# nrf9230_application register map
Vendor: Nordic Semiconductor; Series: nRF92; File version: 1
CPU: CM33 r0p4, little endian, MPU, FPU, 3 interrupt priority bits, 480 interrupts, 8 SAU regions
Registers are 32-bit, read-write, reset 0x0 unless marked. A register's access mark holds for its fields unless they carry their own. Offsets are from the block's base; [hi:lo] are bit positions; lines under a group give offsets from that group; {n}, {i} and the like mark numbered series.

## CPUCONF_NS — CPU Configuration 0
Base 0x42011000
Same registers: CPUCONF_S 0x52011000
0x00 TASKS_ERASECACHE wo — Erase the caches used by the CPU.
  [0] TASKS_ERASECACHE
    1=Trigger task
0x500 INITSVTOR reset 0xE0000000 — Initial value of the secure VTOR (Vector Table Offset Register) after CPU reset.
  [31:0] INITSVTOR — Initial value of the VTOR.
0x504 INITNSVTOR reset 0xE0000000 — Initial value of the non-secure VTOR (Vector Table Offset Register).
  [31:0] INITNSVTOR — Initial value of the VTOR.
0x508 CPUSTART — Enable for starting the CPU
  [0] EN — Enable to start the CPU.
    0=Stopped (CPU stopped.); 1=Started (CPU started.)
0x50C CPUWAIT — Enable for the CPU wait.
  [0] EN — Enable to the CPU wait.
    0=Disabled (CPU is not waiting.); 1=Enabled (CPU is waiting.)

## MEMCONF_NS — Memory configuration 0
Base 0x42012000
Same registers: MEMCONF_S 0x52012000
{0x500+0x10*i} POWER[{i}] (i=0..1) group — Unspecified
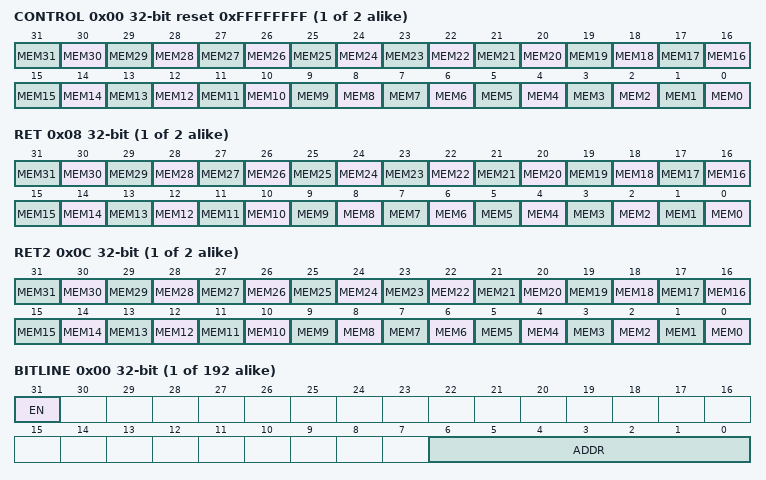
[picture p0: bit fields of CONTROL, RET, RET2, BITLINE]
  0x00 CONTROL reset 0xFFFFFFFF — Description cluster: Control memory block power.
    [all] fields
      0=Off (Power down); 1=On (Power up)
    [n] MEM{n} (n=0..31) — Keep the memory block MEM[{n}] on or off when in System ON mode.
  0x08 RET — Description cluster: RAM retention for RAM [n].
    [all] fields
      0=Off (Retention off); 1=On (Retention on)
    [n] MEM{n} (n=0..31) — Keep the RAM block MEM[{n}] retained when the parent power domain of the RAM is off.
  0x0C RET2 — Description cluster: RAM retention for the second bank in the RAM block
    [all] fields
      0=Off (Retention off); 1=On (Retention on)
    [n] MEM{n} (n=0..31) — Keep the second bank in RAM block MEM[{n}] retained when parent power domain of the RAM is off.
{0x600+4i} REPAIR[{i}] (i=0..191) group — Unspecified
  0x00 BITLINE — Description cluster: Repair configuration for RAM blocks.
    [31] EN — Enable bitline repair
      0=Disabled (Repair disabled.); 1=Enabled (Repair enabled.)
    [6:0] ADDR — Repair address of the bitline
{0x900+4i} BLOCKTYPE[{i}] (i=0..63) group — Unspecified
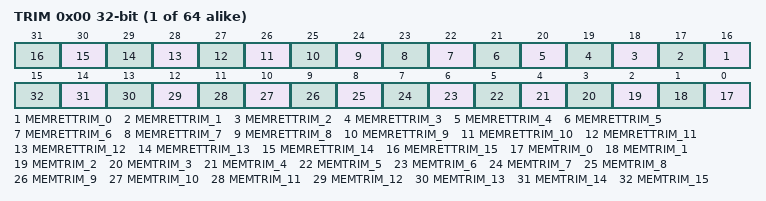
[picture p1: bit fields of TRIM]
  0x00 TRIM — Description cluster: Trim configuration for the memory block types.
    [n+16] MEMRETTRIM_{n} (n=0..15) — Trimming for retention mode for decreased leakage. Must be kept active in RAM retention mode.
    [n] MEMTRIM_{n} (n=0..15) — Read/write margin trim.

## RESETINFO_S — RESETINFO
Base 0x5201E000; alternate view of LRCCONF010_S
0x4A0 RESETREAS group — Unspecified
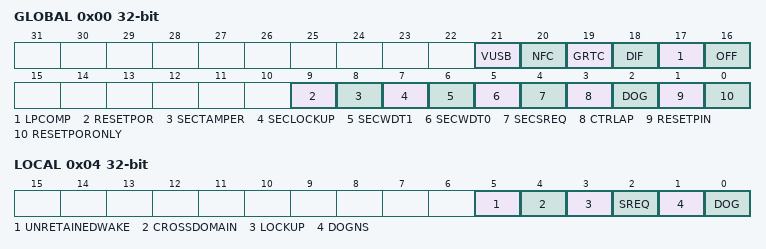
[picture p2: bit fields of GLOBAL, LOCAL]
  0x00 GLOBAL — Global reset reason.
    [all] fields
      0=NotDetected; 1=Detected
    [21] VUSB — Reset after wakeup from System OFF mode due to VBUS rising into valid range.
    [20] NFC — Reset due to wakeup from System OFF mode when wakeup is triggered by NFC field detection in sense mode.
    [19] GRTC — Reset due to wakeup from System OFF mode when wakeup is triggered by GRTC interrupt.
    [18] DIF — Reset due to wakeup from System OFF mode when wakeup is triggered by entering the debug interface mode.
    [17] LPCOMP — Reset due to wakeup from System OFF mode when wakeup is triggered by LPCOMP (Low Power Comparator).
    [16] OFF — Reset due to wakeup from System OFF mode when wakeup is triggered by DETECT signal from GPIO.
    [9] RESETPOR — Reset from power on reset (reset reason other than POR or BOR).
    [8] SECTAMPER — Reset due to secure domain tamper detected
    [7] SECLOCKUP — Reset due to secure domain lockup.
    [6] SECWDT1 — Reset due to the second instance of watchdog timer in secure domain detected.
    [5] SECWDT0 — Reset due to the first instance of watchdog timer in secure domain detected.
    [4] SECSREQ — Reset due to secure domain system reset request.
    [3] CTRLAP — Reset from CTRL-AP detected.
    [2] DOG — Reset from the SysCtrl watchdog timer detected.
    [1] RESETPIN — Reset from pin reset detected.
    [0] RESETPORONLY — Reset from power on reset (reset reason POR or BOR).
  0x04 LOCAL — Local reset reason.
    [5] UNRETAINEDWAKE — Reset due to wake from unretained state.
    [4] CROSSDOMAIN — Reset due to cross domain reset source.
      0=NotDetected; 1=Detected
    [3] LOCKUP — Reset from local CPU lockup detected
      0=NotDetected; 1=Detected
    [2] SREQ — Reset from the local soft reset request detected.
      0=NotDetected; 1=Detected
    [1] DOGNS — Reset from the local non-secure watchdog timer detected
      0=NotDetected; 1=Detected
    [0] DOG — Reset from the local watchdog timer detected
      0=NotDetected; 1=Detected
0x4A8 ERROR group — Unspecified
  0x00 STATUS — Reset error status.
    [3:0] ERRORSTATUS
  0x04 ADDRESS — Reset error address.
    [31:0] ERRORADDRESS
0x4C0 RESTOREVALID — Valid restore image is present in RAM.
  [0] RESTOREVALID
    0=NotPreset (Not present); 1=Present
0x4C4 MASKLOCKUP — Mask CPU lockup signal.
  [0] MASK — Mask lockup signal
    0=NotMask (Do not mask lockup signal); 1=Mask lockup signal
